AUTOSAR XML (schema 4-2-2)
standard types defined: float32, uint8
package /ASW_COM_Pkg
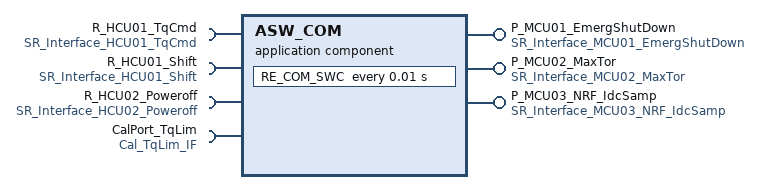
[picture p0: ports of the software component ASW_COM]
  application sw component type ASW_COM
    provide port P_MCU01_EmergShutDown: nonqueued-sender-com-spec{data-element=DE_MCU01_EmergShutDown, init-value=0}, provided-interface=SR_Interface_MCU01_EmergShutDown
    provide port P_MCU02_MaxTor: nonqueued-sender-com-spec{data-element=DE_MCU02_MaxTor, init-value=0}, provided-interface=SR_Interface_MCU02_MaxTor
    provide port P_MCU03_NRF_IdcSamp: nonqueued-sender-com-spec{data-element=DE_MCU03_NRF_IdcSamp, init-value=0}, provided-interface=SR_Interface_MCU03_NRF_IdcSamp
    4 x require port:
      R_HCU01_TqCmd: nonqueued-receiver-com-spec{data-element=DE_HCU01_TqCmd, init-value=0}, required-interface=SR_Interface_HCU01_TqCmd
      R_HCU01_Shift: nonqueued-receiver-com-spec{data-element=DE_HCU01_Shift, init-value=0}, required-interface=SR_Interface_HCU01_Shift
      R_HCU02_Poweroff: nonqueued-receiver-com-spec{data-element=DE_HCU02_Poweroff, alive-timeout=0.3, init-value=0}, required-interface=SR_Interface_HCU02_Poweroff
      CalPort_TqLim: parameter-require-com-spec{alive-timeout=0.3, init-value=0, parameter=TqLim_Val}, required-interface=Cal_TqLim_IF
    behavior IB_ASW_COM
      timing event TE_RE_COM_SWC_10ms: start-on-event=RE_COM_SWC, period=0.01
      runnable RE_COM_SWC
        data-receive-point-by-arguments:
          access REC_HCU01_TqCmd: accessed-variable=R_HCU01_TqCmd.DE_HCU01_TqCmd
          access REC_HCU01_Shift: accessed-variable=R_HCU01_Shift.DE_HCU01_Shift
          access REC_HCU02_Poweroff: accessed-variable=R_HCU02_Poweroff.DE_HCU02_Poweroff
        data-send-points:
          access SEND_MCU01_EmergShutDown: accessed-variable=P_MCU01_EmergShutDown.DE_MCU01_EmergShutDown
          access SEND_MCU02_MaxTor: accessed-variable=P_MCU02_MaxTor.DE_MCU02_MaxTor
          access SEND_MCU03_NRF_IdcSamp: accessed-variable=P_MCU03_NRF_IdcSamp.DE_MCU03_NRF_IdcSamp
        parameter access ACCESS_CalPort_TqLim: accessed-parameter=CalPort_TqLim.TqLim_Val
package /COM_Interface
  6 x sender receiver interface:
    SR_Interface_MCU01_EmergShutDown
      data DE_MCU01_EmergShutDown: type=dt_Flag
    SR_Interface_MCU02_MaxTor
      data DE_MCU02_MaxTor: type=dt_Tq
    SR_Interface_MCU03_NRF_IdcSamp
      data DE_MCU03_NRF_IdcSamp: type=dt_Idc
    SR_Interface_HCU01_TqCmd
      data DE_HCU01_TqCmd: type=dt_Tq
    SR_Interface_HCU01_Shift
      data DE_HCU01_Shift: type=dt_Shift
    SR_Interface_HCU02_Poweroff
      data DE_HCU02_Poweroff: type=dt_Power
  parameter interface Cal_TqLim_IF
    parameter data prototype TqLim_Val: type=dt_TqLim
package /DataTypes
  6 x impl type, all with category=VALUE:
    dt_Tq: base-type=float32
    dt_Shift: base-type=uint8
    dt_Flag: base-type=uint8
    dt_Power: base-type=uint8
    dt_Idc: base-type=float32
    dt_TqLim: base-type=float32
